# R7FA2E307 register map
Vendor: Renesas Electronics Corporation; Series: RA2; File version: 1.20.00
CPU: CM23 r1p0, little endian, MPU, no FPU, VTOR, 2 interrupt priority bits, 32 interrupts
Registers are 8-bit, read-write, reset 0x0 unless marked. A register's access mark holds for its fields unless they carry their own. Offsets are from the block's base; [hi:lo] are bit positions; {n}, {i} and the like mark numbered series.

## ICU — ICU for CPU
Base 0x40006000
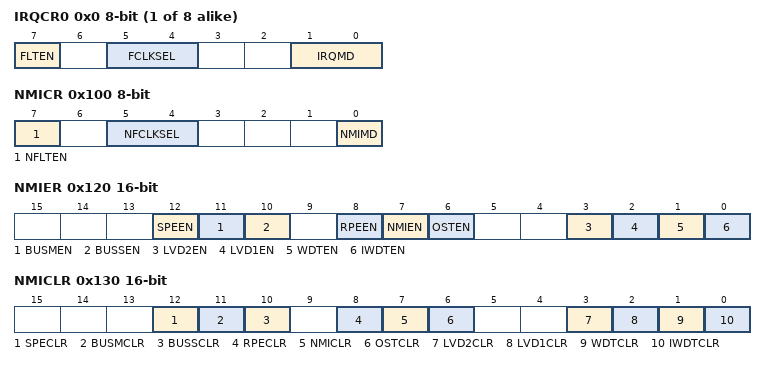
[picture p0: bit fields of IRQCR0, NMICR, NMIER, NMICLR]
{0x0+i} IRQCR{i} (i=0..7) — IRQ Control Register {i}
  [7] FLTEN — IRQi Digital Filter Enable
  [5:4] FCLKSEL — IRQi Digital Filter Sampling Clock Select
  [1:0] IRQMD — IRQi Detection Sense Select
0x100 NMICR — NMI Pin Interrupt Control Register
  [7] NFLTEN — NMI Digital Filter Enable
  [5:4] NFCLKSEL — NMI Digital Filter Sampling Clock Select
  [0] NMIMD — NMI Detection Set
0x120 NMIER 16-bit — Non,Maskable Interrupt Enable Register
  [12] SPEEN — CPU Stack Pointer Monitor Interrupt Enable
  [11] BUSMEN — Bus Master MPU Error Interrupt Enable
  [10] BUSSEN — Bus Slave MPU Error Interrupt Enable
  [8] RPEEN — SRAM Parity Error Interrupt Enable
  [7] NMIEN — NMI Pin Interrupt Enable
  [6] OSTEN — Main Clock Oscillation Stop Detection Interrupt Enable
  [3] LVD2EN — Voltage monitor 2 Interrupt Enable
  [2] LVD1EN — Voltage monitor 1 Interrupt Enable
  [1] WDTEN — WDT Underflow/Refresh Error Interrupt Enable
  [0] IWDTEN — IWDT Underflow/Refresh Error Interrupt Enable
0x130 NMICLR 16-bit — Non,Maskable Interrupt Status Clear Register
  [12] SPECLR — CPU Stack Pointer Monitor Interrupt Status Flag Clear
  [11] BUSMCLR — Bus Master MPU Error Interrupt Status Flag Clear
  [10] BUSSCLR — Bus Slave MPU Error Interrupt Status Flag Clear
  [8] RPECLR — SRAM Parity Error Interrupt Status Flag Clear
  [7] NMICLR — NMI Pin Interrupt Status Flag Clear
  [6] OSTCLR — Oscillation Stop Detection Interrupt Status Flag Clear
  [3] LVD2CLR — Voltage Monitor 2 Interrupt Status Flag Clear
  [2] LVD1CLR — Voltage Monitor 1 Interrupt Status Flag Clear
  [1] WDTCLR — WDT Underflow/Refresh Error Interrupt Status Flag Clear
  [0] IWDTCLR — IWDT Underflow/Refresh Error Interrupt Status Flag Clear
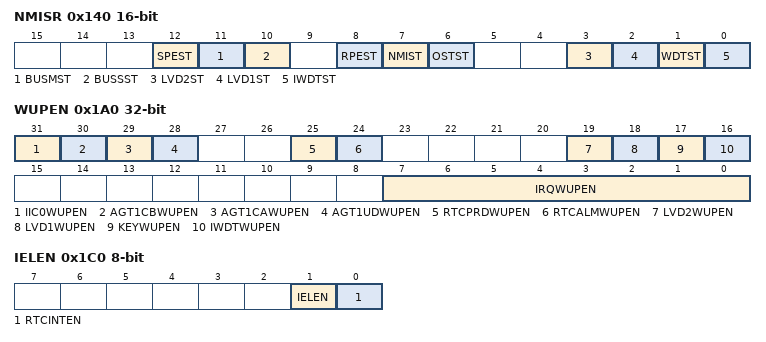
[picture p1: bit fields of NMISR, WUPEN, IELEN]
0x140 NMISR 16-bit ro — Non,Maskable Interrupt Status Register
  [12] SPEST — CPU Stack Pointer Monitor Interrupt Status Flag
  [11] BUSMST — Bus Master MPU Error Interrupt Status Flag
  [10] BUSSST — Bus Slave MPU Error Interrupt Status Flag
  [8] RPEST — SRAM Parity Error Interrupt Status Flag
  [7] NMIST — NMI Pin Interrupt Status Flag
  [6] OSTST — Main Clock Oscillation Stop Detection Interrupt Status Flag
  [3] LVD2ST — Voltage Monitor 2 Interrupt Status Flag
  [2] LVD1ST — Voltage Monitor 1 Interrupt Status Flag
  [1] WDTST — WDT Underflow/Refresh Error Interrupt Status Flag
  [0] IWDTST — IWDT Underflow/Refresh Error Interrupt Status Flag
0x1A0 WUPEN 32-bit — Wake Up Interrupt Enable Register
  [31] IIC0WUPEN — IIC0 Address Match Interrupt Software Standby/Snooze Mode Returns Enable
  [30] AGT1CBWUPEN — AGT1 Compare Match B Interrupt Software Standby/Snooze Mode Returns Enable
  [29] AGT1CAWUPEN — AGT1 Compare Match A Interrupt Software Standby/Snooze Mode Returns Enable
  [28] AGT1UDWUPEN — AGT1 Underflow Interrupt Software Standby/Snooze Mode Returns Enable
  [25] RTCPRDWUPEN — RTC Period Interrupt Software Standby/Snooze Mode Returns Enable
  [24] RTCALMWUPEN — RTC Alarm Interrupt Software Standby/Snooze Mode Returns Enable
  [19] LVD2WUPEN — LVD2 Interrupt Software Standby/Snooze Mode Returns Enable
  [18] LVD1WUPEN — LVD1 Interrupt Software Standby/Snooze Mode Returns Enable
  [17] KEYWUPEN — Key Interrupt Software Standby/Snooze Mode Returns Enable
  [16] IWDTWUPEN — IWDT Interrupt Software Standby/Snooze Mode Returns Enable
  [7:0] IRQWUPEN — IRQ Interrupt Software Standby/Snooze Mode Returns Enable
0x1C0 IELEN — ICU event Enable Register
  [1] IELEN — Parts Asynchronous Interrupts Enable except RTC (when LPOPTEN bit = 1)
  [0] RTCINTEN — RTCALM and RTCPRD Interrupts Enable (when LPOPTEN bit = 1)
0x200 SELSR0 16-bit — SYS Event Link Setting Register
{0x300+4i} IELSR{i} (i=0..31) 32-bit — ICU Event Link Setting Register {i}
